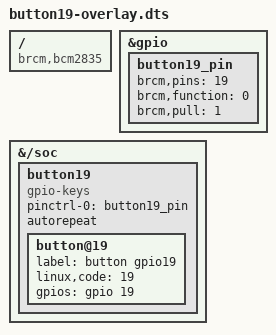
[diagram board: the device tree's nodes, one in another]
/dts-v1/;
/plugin/;

/ {
    compatible = "brcm,bcm2835", "brcm,bcm2708", "brcm,bcm2709";

    fragment@0 {
        target = <&gpio>;
        __overlay__ {
            button19_pin: button19_pin {
                brcm,pins = <19>;     /* gpio19 */
                brcm,function = <0>; /* input */
                brcm,pull = <1>;     /* pull-down */
            };
        };
    };

    fragment@1 {
    target-path = "/soc";
        __overlay__ {
            button19: button19 {
                compatible = "gpio-keys";
                #address-cells = <1>;
                #size-cells = <0>;
                pinctrl-names = "default";
                pinctrl-0 = <&button19_pin>;
                status = "okay";
                autorepeat;

                button@19 {
                    label = "button gpio19";
                    linux,code = <19>;
                    gpios = <&gpio 19 0>;
                };
            };
        };
    };
};

